AUTOSAR XML (schema 00050)
standard types defined: Boolean, Float
package /ARRoot
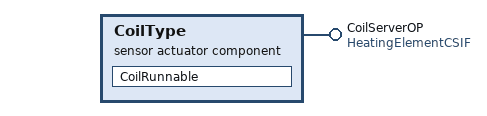
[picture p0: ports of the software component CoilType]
  sensor actuator sw component type CoilType
    provide port CoilServerOP: provided-interface=HeatingElementCSIF
    behavior CoilIB
      runnable CoilRunnable: external-triggering-point=CoilServerOP.TriggerForCoil
  swc implementation CoilTypeImplFile: programming-language=C, behavior=CoilIB
  trigger interface ExternalTriggerForCoil
    trigger TriggerForCoil
  client server interface HeatingElementCSIF: client-server-operation
  swc implementation HeatingElementImplFile: programming-language=C, behavior=SeatHeatingIB
  swc implementation LedDialImplFile: programming-language=C, behavior=LedDialIB
  sender receiver interface LedDialSRIF
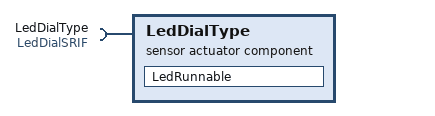
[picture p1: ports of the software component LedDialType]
  sensor actuator sw component type LedDialType
    require port LedDialType: required-interface=LedDialSRIF
    behavior LedDialIB
      runnable LedRunnable: variable-access
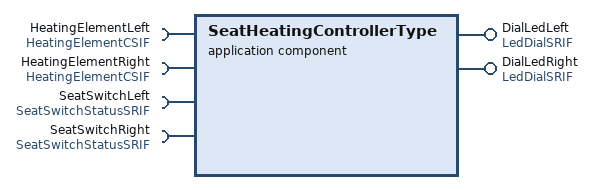
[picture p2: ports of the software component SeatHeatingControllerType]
  application sw component type SeatHeatingControllerType
    provide port DialLedLeft: provided-interface=LedDialSRIF
    provide port DialLedRight: provided-interface=LedDialSRIF
    4 x require port:
      HeatingElementLeft: required-interface=HeatingElementCSIF
      HeatingElementRight: required-interface=HeatingElementCSIF
      SeatSwitchLeft: required-interface=SeatSwitchStatusSRIF
      SeatSwitchRight: required-interface=SeatSwitchStatusSRIF
    behavior SeatHeatingIB
      6 x runnable:
        DialLedLeftRunnable: variable-access
        DialLedRightRunnable: variable-access
        HeatingElementLeftRunnable: synchronous-server-call-point=HeatingElementLeft.
        HeatingElementRightRunnable: synchronous-server-call-point=HeatingElementRight.
        SeatSwitchLeftRunnable: variable-access
        SeatSwitchRightRunnable: variable-access
  sender receiver interface SeatSwitchStatusSRIF
